# spc_reva register map
Registers are access not given, no defined reset value unless marked. A register's access mark holds for its fields unless they carry their own. Offsets are from the block's base; lines under a group give offsets from that group; [hi:lo] are bit positions; {n}, {i} and the like mark numbered series; 'fields as' and 'values as' point back to an identical list; <NAME> marks a mode.

## Memory map
0x50090000 SPC size 0x1000 — Secure Privilege Controller.

## SPC — Secure Privilege Controller.
Base 0x50090000
0x00 CTRL 32-bit — SPC Secure Configuration Control Register.
  [0] LOCK — Write 1 to set, disables writes to security-related control registers in the SPC. Once set, the locked registers cannot be modified nor can this bit be cleared to 0 except through a reset.
0x08 RESP 32-bit — Security Violation Response Configuration Register.
  [0] VIOLCFG — This field configures the target response in case of a secuirty violation.
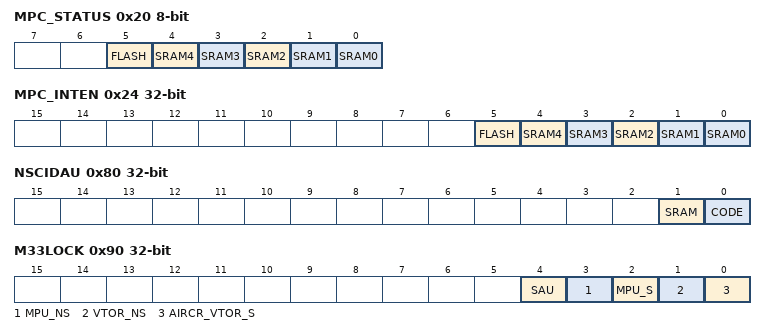
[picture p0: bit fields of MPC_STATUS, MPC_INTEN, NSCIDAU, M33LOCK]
0x20 MPC_STATUS 8-bit ro — Secure MPC Status Register.
  [5] FLASH — Interrupt status for Flash Memory Protection Controllers.
  [n] SRAM{n} (n=1..4) — Interrupt status for SRAM{n} Memory Protection Controllers.
  [0] SRAM0 — Interrupt status for SRAM 0 Memory Protection Controller.
0x24 MPC_INTEN — Secure MPC Interrupt Enable Register.
  [5] FLASH — Interrupt enable for Flash Memory Protection Controllers.
  [n] SRAM{n} (n=1..4) — Interrupt enable for SRAM{n} Memory Protection Controllers.
  [0] SRAM0 — Interrupt enable for SRAM 0 Memory Protection Controller.
0x30 PPC_STATUS ro — Secure PPC Interrupt Status Register.
  [1:0] APBPPC — Interrupt Status of APB PPC for targets on APB bus. Each bit ties to an individual PPC in the system.
0x34 PPC_INTCLR wo — Secure PPC Interrupt Clear Register.
  [1:0] APBPPC — Interrupt Clear of APB PPC for targets on the APB bus. Each bit ties to an individual PPC in the system.
0x38 PPC_INTEN — Secure PPC Interrupt Enable Register.
  [1:0] APBPPC — Interrupt Enable for APB PPC for targets on the APB bus. Each bit ties to an individual PPC in the system.
0x80 NSCIDAU — Non-Secure Callabale IDAU Configuration Register.
  [1] SRAM — Configures whether the RAM region is Non-secure Callable.
  [0] CODE — Configures whether the CODE region is Non-secure Callable.
0x90 M33LOCK — M33 Core Register Lock Configuratrion Register.
  [4] SAU — Lock Security Attribution Unit (SAU).
    0=DIS (TX DMA requests are disabled, andy pending DMA requests are cleared.); 1=en (TX DMA requests are enabled.)
  [3] MPU_NS — Lock non-secure MPU registers.
  [2] MPU_S — Lock secure MPU registers.
  [1] VTOR_NS — Lock VTOR_NS register.
  [0] AIRCR_VTOR_S — Lock VTOR_S, AIRCR.PRIS, and AIRCR.BFHFNMINS.
0x120 APBSEC — APB Target Secure/Non-secure PPC Access Register.
  [31:0] PERIPH — Each bit configures the APB PPC to enforce the security access allowed for an individual peripheral.
0x160 APBPRIV — APB Tartet Privileged/Non-privileged PPC Access Register.
  fields as APBSEC
0x180 GPIO0 — Secure GPIO0 Configuration Register.
  [11:0] PINS — Each bit configures a GPIO pin as secore or non-secure on GPIO Port 0. Secure GPIO pins prevent software from reading GPIO Data In pin states.
0x184 GPIO1 — Secure GPIO1 Configuration Register.
  [1:0] PINS — Each bit configures a GPIO pin as secore or non-secure on GPIO Port 0. Secure GPIO pins prevent software from reading GPIO Data In pin states.
